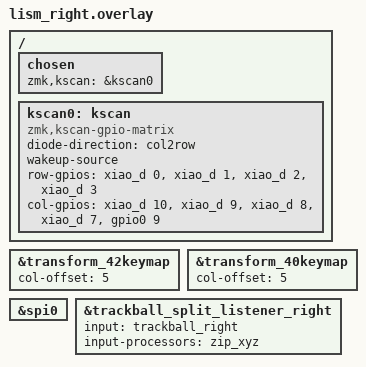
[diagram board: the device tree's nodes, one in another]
#include "lism.dtsi"
#include "paw3222-right.dtsi"
#include "split_input.dtsi"
#include "lism-layouts.dtsi"
#include <input/processors/xyz.dtsi>
#include <dt-bindings/zmk/input_transform.h>
// #include <input/processors/report_rate_limit.dtsi>

&transform_42keymap {
    col-offset = <5>;
};

&transform_40keymap {
    col-offset = <5>;
};

&spi0 {
    status = "okay";
};

&trackball_split_listener_right { // local trackball *split* input device child node
	input = <&trackball_right>;
	input-processors =
		<&zip_xyz>; // compressor by badjeff
};

/ {
	chosen {
		zmk,kscan = &kscan0;
	};

	kscan0: kscan {
		compatible = "zmk,kscan-gpio-matrix";
		diode-direction = "col2row";
        wakeup-source;

        row-gpios
            = <&xiao_d 0 (GPIO_ACTIVE_HIGH | GPIO_PULL_DOWN)>   // row0: D0
            , <&xiao_d 1 (GPIO_ACTIVE_HIGH | GPIO_PULL_DOWN)>   // row1: D1
            , <&xiao_d 2 (GPIO_ACTIVE_HIGH | GPIO_PULL_DOWN)>   // row2: D2
            , <&xiao_d 3 (GPIO_ACTIVE_HIGH | GPIO_PULL_DOWN)>   // row3: D3
            ; 

        col-gpios
            = <&xiao_d 10 GPIO_ACTIVE_HIGH>                     // col0: D10
            , <&xiao_d 9  GPIO_ACTIVE_HIGH>                     // col1: D9
            , <&xiao_d 8  GPIO_ACTIVE_HIGH>                     // col2: D8
            , <&xiao_d 7  GPIO_ACTIVE_HIGH>                     // col3: D7
            , <&gpio0  9  GPIO_ACTIVE_HIGH>                     // col4: GPIO9(NFC1)
            ; 
    };
};
